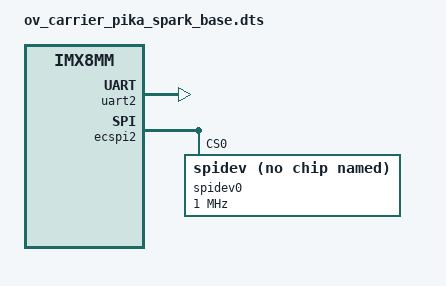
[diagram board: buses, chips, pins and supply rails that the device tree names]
/**
 * Portenta-X8 dtb overlay file
 * Pika Spark carrier board base configuration
 * Enables RS-485 on UART2 and BNO085 IMU on ecspi2
 */

/dts-v1/;
/plugin/;

#include <dt-bindings/clock/imx8mm-clock.h>
#include <dt-bindings/gpio/gpio.h>
#include "imx8mm-pinfunc.h"

/ {
	compatible = "fsl,imx8mm-evk", "fsl,imx8mm";

	/* Pins mux and pad configuration */
	fragment@0 {
		target = <&iomuxc>;
		__overlay__ {
			imx8mm {
				/* BNO085 IMU GPIO pins (nIRQ, nBOOT, nRST) */
				pinctrl_bno085: bno085grp {
					fsl,pins = <
						/* nBNO085_IRQ - GPIO5_IO3 (SPDIF_TX), J1 pin 74 */
						MX8MM_IOMUXC_SPDIF_TX_GPIO5_IO3			0x110
						/* nBNO085_BOOT - GPIO3_IO23 (SAI5_RXD2), J1 pin 56 */
						MX8MM_IOMUXC_SAI5_RXD2_GPIO3_IO23		0x110
						/* nBNO085_RST - GPIO3_IO22 (SAI5_RXD1), J1 pin 58 */
						MX8MM_IOMUXC_SAI5_RXD1_GPIO3_IO22		0x110
					>;
				};

				/* Pins RS-485 */
				pinctrl_uart2: uart2grp {
					fsl,pins = <
						MX8MM_IOMUXC_SAI3_TXFS_UART2_DCE_RX		0x140
						MX8MM_IOMUXC_SAI3_TXC_UART2_DCE_TX		0x140
						MX8MM_IOMUXC_SAI3_RXC_UART2_DCE_CTS_B		0x140
						MX8MM_IOMUXC_SAI3_RXD_UART2_DCE_RTS_B		0x140
					>;
				};
			};
		};
	};

	/* RS-485 */
	fragment@1 {
		target = <&uart2>;
		__overlay__ {
			pinctrl-names = "default";
			pinctrl-0 = <&pinctrl_uart2>;
			assigned-clocks = <&clk IMX8MM_CLK_UART2>;
			assigned-clock-parents = <&clk IMX8MM_SYS_PLL1_80M>;
			linux,rs485-enabled-at-boot-time;
			/*rs485-rx-during-tx;*/
			rs485-rts-active-high;
			fsl,uart-has-rtscts;
			status = "okay";
		};
	};

	/* BNO085 IMU on ecspi2 */
	fragment@2 {
		target = <&ecspi2>;
		__overlay__ {
			status = "okay";
			pinctrl-names = "default";
			pinctrl-0 = <&pinctrl_bno085>;
			spidev0: spidev@0 {
				compatible = "rohm,dh2228fv";
				spi-max-frequency = <1000000>;
				reg = <0>;
			};
		};
	};
};
